AUTOSAR XML (schema 4-2-2)
standard types defined: uint8, sint8, uint16, uint32
package /Cluster
  can cluster Body: baudrate=500000, can-fd-baudrate=2000000
    can physical channel Channel
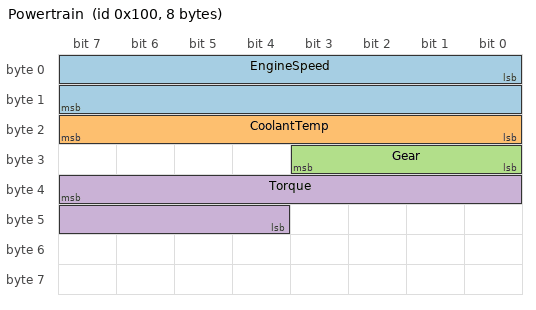
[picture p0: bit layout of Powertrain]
      frame Powertrain: id 0x100, from ECU_A, to ECU_B ECU_C, frame-length=8, can-addressing-mode=STANDARD, can-frame-rx-behavior=CAN-20, can-frame-tx-behavior=CAN-20
        pdu Powertrain_PDU: length=8, minimum-delay=0.02, transmission-mode-true-timing=cyclic-timing=time-period=0.1, unused-bit-pattern=0
          signal EngineSpeed: start 0, 16 bit, little-endian, base-type=uint16, compu {phys=raw*0.25 for raw 0..65535; unit rpm}, range phys 0..8000, transfer-property=PENDING  # Engine speed & direction
          signal CoolantTemp: start 16, 8 bit, little-endian, base-type=sint8, compu {phys=raw-20 for raw -128..127; unit °C}, range raw -100..100, transfer-property=PENDING
          signal Gear: start 24, 4 bit, little-endian, base-type=uint8, compu {0=Neutral, 1=First, 15=Reverse}, transfer-property=TRIGGERED
          signal Torque: start 39, 12 bit, big-endian, base-type=uint16, unit=Nm, compu {phys=raw*0.5-500; unit Nm}, transfer-property=PENDING
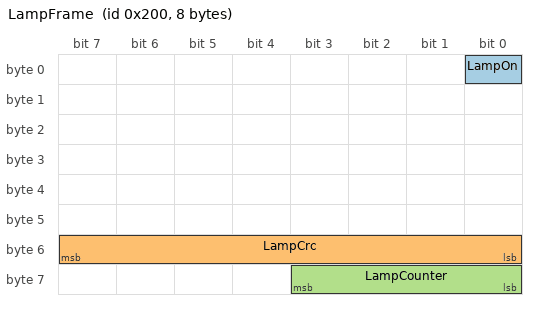
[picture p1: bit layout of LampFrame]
      frame LampFrame: id 0x200, from ECU_B, to ECU_A, frame-length=8, can-addressing-mode=STANDARD
        pdu LampFrame_PDU: length=8, minimum-delay=0.01, transmission-mode-true-timing={cyclic-timing=time-period=1.0E-1, event-controlled-timing=number-of-repetitions=0}
          signal LampOn: start 0, 1 bit, little-endian, transfer-property=TRIGGERED
          signal LampCrc: start 48, 8 bit, little-endian, transfer-property=PENDING
          signal LampCounter: start 56, 4 bit, little-endian, transfer-property=PENDING
      frame SecureFrame: id 0x300, from ECU_B, to ECU_A, frame-length=8, can-addressing-mode=STANDARD
        secured i pdu Secure_PDU: length=8, payload=PT_Secure_Payload, secure-communication-props={auth-info-tx-length=32, data-id=43, freshness-value-id=1, freshness-value-length=64, freshness-value-tx-length=8}, use-as-cryptographic-i-pdu=false
      frame Wide: id 0x1ABCDE, from ECU_C, frame-length=16, can-addressing-mode=EXTENDED, can-frame-rx-behavior=CAN-FD, can-frame-tx-behavior=CAN-FD
        pdu Wide_PDU: length=16, transmission-mode-true-timing=event-controlled-timing=number-of-repetitions=0
          signal Odometer: start 64, 32 bit, little-endian, base-type=uint32, compu {phys=raw*0.1; unit km}, transfer-property=PENDING
      frame DiagReq: id 0x7E0, to ECU_A, frame-length=8, can-addressing-mode=STANDARD
        n pdu DiagReq_NPDU: length=8
      pdu triggering PT_Secure_Payload: pdu=SecurePayload_PDU
package /PDUs
  pdu SecurePayload_PDU: length=3, transmission-mode-true-timing=cyclic-timing=time-period=0.05
    signal Rpm: start 0, 16 bit, little-endian, transfer-property=PENDING
package /Units
  4 x unit:
    rpm: display-name=rpm
    degC: display-name=°C
    Nm: display-name=Nm
    km: display-name=km
package /E2E
  end to end protection set Protections
    end to end protection LampFrame_E2E: end-to-end-profile={category=PROFILE_01, counter-offset=56, crc-offset=48, data-id-mode=ALL-16-BIT, data-ids=42, data-length=64}, end-to-end-protection-i-signal-i-pdu{data-length=64, data-offset=0, i-signal-i-pdu=LampFrame_PDU}
package /PduGroups
  6 x i signal i pdu group:
    ECU_A_Tx: communication-direction=OUT, i-signal-i-pdus=Powertrain_PDU
    ECU_A_Rx: communication-direction=IN, i-signal-i-pdus=[LampFrame_PDU, SecurePayload_PDU]
    ECU_B_Tx: communication-direction=OUT, i-signal-i-pdus=[LampFrame_PDU, SecurePayload_PDU]
    ECU_B_Rx: communication-direction=IN, i-signal-i-pdus=Powertrain_PDU
    ECU_C_Tx: communication-direction=OUT, i-signal-i-pdus=Wide_PDU
    ECU_C_Rx: communication-direction=IN, i-signal-i-pdus=Powertrain_PDU
package /ECUs
  ecu instance ECU_A: associated-com-i-pdu-group=[ECU_A_Tx, ECU_A_Rx]
    can communication connector Conn
  ecu instance ECU_B: associated-com-i-pdu-group=[ECU_B_Tx, ECU_B_Rx]
    can communication connector Conn
  ecu instance ECU_C: associated-com-i-pdu-group=[ECU_C_Tx, ECU_C_Rx]
    can communication connector Conn
